# USB0_VBP2APB_WRAP_CONTROLLER_VBP_CORE_ADDR_MAP register map
Vendor: Texas Instruments
Registers are 32-bit, access per field, reset 0x0 unless marked. A register's access mark holds for its fields unless they carry their own. Offsets are as the file gives them; [hi:lo] are bit positions; {n}, {i} and the like mark numbered series; 'fields as' and 'values as' point back to an identical list.

## USB0_VBP2APB_WRAP_CONTROLLER_VBP_CORE_ADDR_MAP (part 4 of 9)
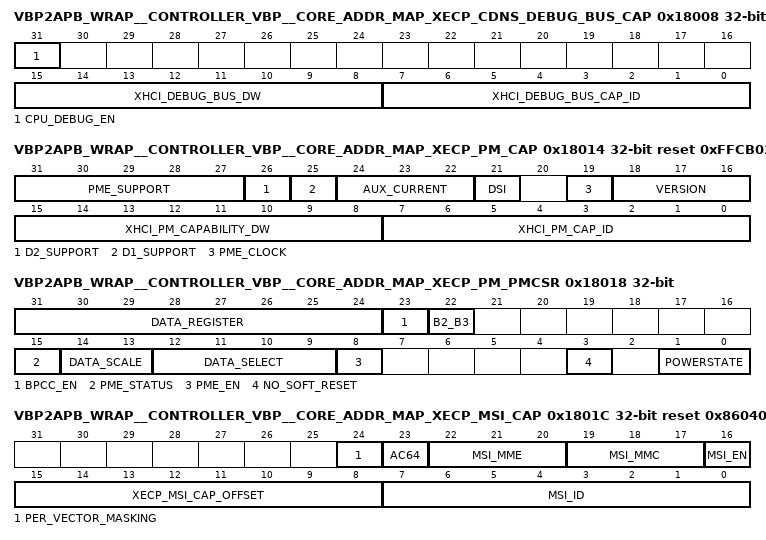
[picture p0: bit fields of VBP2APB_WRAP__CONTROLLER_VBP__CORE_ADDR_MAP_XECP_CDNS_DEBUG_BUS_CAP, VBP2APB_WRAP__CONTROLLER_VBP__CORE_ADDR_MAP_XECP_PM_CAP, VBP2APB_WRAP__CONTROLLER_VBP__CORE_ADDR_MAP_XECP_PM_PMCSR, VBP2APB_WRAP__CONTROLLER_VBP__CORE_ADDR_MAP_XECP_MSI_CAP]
0x18008 VBP2APB_WRAP__CONTROLLER_VBP__CORE_ADDR_MAP_XECP_CDNS_DEBUG_BUS_CAP reset 0x3C4 — xHCI Debug Bus Capability. This is a vendor defined capability. Please refer to Integration Guide for further details of debug bus usage.
  [31] CPU_DEBUG_EN rw — Debug Bus Enable, RW. When 0, allows the xhci_debug_sel primary input to control selection of Debug Bus sources. When 1, allows the cpu_debug_bus_sel field in the XECP_CDNS_DEBUG_BUS_CTRL register to control selection of Debug Bus sources. Default value after reset is '0'.
  [15:8] XHCI_DEBUG_BUS_DW ro — Next Capability Pointer, RO. This field indicates the location of the next capability with respect to the effective address of this capability.
  [7:0] XHCI_DEBUG_BUS_CAP_ID ro — Capability ID, RO. This field identifies the extended capability. For xHCI Debug Bus its' value is 196.
0x1800C VBP2APB_WRAP__CONTROLLER_VBP__CORE_ADDR_MAP_XECP_CDNS_DEBUG_BUS_CTRL — xHCI Debug Bus Control. This is a vendor defined capability. Please refer to Integration Guide for further details of debug bus usage.
  [4:0] CPU_DEBUG_BUS_SEL rw — Debug Bus Select, RW. Value of this field determines a source of Debug Bus. Default value after reset is 0.
0x18010 VBP2APB_WRAP__CONTROLLER_VBP__CORE_ADDR_MAP_XECP_CDNS_DEBUG_BUS_STATUS ro — xHCI Debug Bus Status. This is a vendor defined capability. Please refer to Integration Guide for further details of debug bus usage.
  [31:0] XHCI_DEBUG_BUS — Debug Bus, RO. Debug Bus current value. Note for multi-bit probes, this register is only suitable for analysing a static value due to simplified clock domain synchronisation
0x18014 VBP2APB_WRAP__CONTROLLER_VBP__CORE_ADDR_MAP_XECP_PM_CAP reset 0xFFCB0203 — Extended Power Management capability register. Defined in section 7.3 of xHCI specification. Reuses power management structures defined in PCI bus Power Management specification. This register may be read from or written to at any time, including whilst the CNR field in the USBSTS register is high.
  [31:27] PME_SUPPORT ro — Power Management Capabilities: PME_Support. Default = device specific. This 5-bit field indicates the power states in which the function may assert PME#. A value of '0' for any bit indicates that the function is not capable of asserting the PME# signal while in that power state. Encodings: Bit 0 set: X XXX1b - PME# can be asserted from D0, Bit 1 set: X XX1Xb - PME# can be asserted from D1, Bit 2 set: X X1XXb - PME# can be asserted from D2, Bit 3 set: X 1XXXb - PME# can be asserted from D3hot, Bit 4 set: 1 XXXXb - PME# can be asserted from D3cold
  [26] D2_SUPPORT ro — Power Management Capabilities: D2_Support. Default = device specific. If this bit is a '1', this function supports the D2 Power Management State. Functions that do not support D2 must always return a value of '0' for this bit.
  [25] D1_SUPPORT ro — Power Management Capabilities: D1_Support. Default = device specific. If this bit is a '1', this function supports the D1 Power Management State. Functions that do not support D1 must always return a value of '0' for this bit.
  [24:22] AUX_CURRENT rw — Power Management Capabilities: Aux_Current. Default = device specific. This 3 bit field reports the 3.3Vaux auxiliary current requirements for the PCI function. If the Data Register field of XECP_PM_PMCSR has been implemented by this function: - reads of this field must return a value of '000', - the Data Register takes precedence over this field for 3.3Vaux current requirement reporting. If PME# generation from D3cold is not supported by the Function [XECP_PM_CAP[15]='0'], this field must return a value of '000' when read. For functions that support PME# from D3cold, and do not implement the Data Register, the following bit encoding for maximum current required apply : '111': 375 mA, '110': 320 mA, '101': 270 mA, '100': 220 mA, '011': 160 mA, '010': 100 mA, '001': 55 mA, '000': 0 [self powered].
  [21] DSI ro — Power Management Capabilities: DSI. Default = device specific. The Device Specific Initialization bit indicates whether special initialization of this function is required [beyond the standard PCI configuration header] before the generic class device driver is able to use it. Note that this bit is not used by some operating systems. Microsoft Windows and Windows NT, for instance, do not use this bit to determine whether to use D3. Instead, they use the drivers capabilities to determine this. A '1' indicates that the function requires a device specific initialization sequence following transition to the D0 uninitialized state. For more information refer to Section 8.3. of PCI bus Power Management specification.
  [19] PME_CLOCK ro — Power Management Capabilities: PME Clock. Default = '0'. When this bit is a '1', it indicates that the function relies on the presence of the PCI clock for PME# operation. When this bit is a '0', it indicates that no PCI clock is required for the function to generate PME#. Functions that do not support PME# generation in any state must return '0' for this field.
  [18:16] VERSION ro — Power Management Capabilities: Version. Default = '011'. A value of '011' indicates that this function complies with revision 1.2 of the PCI Power Management Interface Specification.
  [15:8] XHCI_PM_CAPABILITY_DW ro — XHCI_PM_CAPABILITY_DW. Next Item Pointer. This field provides an offset pointing to the location of next item in the functions capability list.
  [7:0] XHCI_PM_CAP_ID ro — XHCI_PM_CAP_ID. Power Management capability ID.
0x18018 VBP2APB_WRAP__CONTROLLER_VBP__CORE_ADDR_MAP_XECP_PM_PMCSR access not given — Extended Power Management Control/Status register. Defined in section 7.3 of xHCI specification. Reuses power management structures defined in PCI bus Power Management specification. This register may be read from or written to at any time, including whilst the CNR field in the USBSTS register is high.
  [31:24] DATA_REGISTER ro — Data register. This register is used to report the state dependent data requested by the Data_Select field of XECP_PM_PMCSR register. The value of Data register is scaled by the value reported by the Data_Scale field of XECP_PM_PMCSR register.
  [23] BPCC_EN ro — PMCSR Bridge Support Extensions: BPCC_En [Bus Power/Clock Control Enable]. External strap or internally hardwired. A '1' indicates that the bus power/clock control mechanism as defined in Section 4.7.1 PCI bus Power Management specification is enabled. A '0' indicates that the bus power/clock control policies defined in Section 4.7.1 PCI bus Power Management specification have been disabled. When the Bus Power/Clock Control mechanism is disabled, the bridges Power Management Control/Status Register PowerState field cannot be used by the system software to control the power or clock of the bridges secondary bus.
  [22] B2_B3 ro — PMCSR Bridge Support Extensions: B2_B3# [B2/B3 support for D3hot]. External strap or internally hardwired. The state of this bit determines the action that is to occur as a direct result of programming the function to D3hot. A '1' indicates that when the bridge function is programmed to D3hot, its secondary buss PCI clock will be stopped [B2]. A '0' indicates that when the bridge function is programmed to D3hot, its secondary bus will have its power removed [B3]. This bit is only meaningful if bit BPCC_En of XECP_PM_PMCSR register is a '1'. Refer to Section 4.7.1 of PCI bus Power Management specification for details.
  [15] PME_STATUS — Power Management Control/Status Register: PME_Status. This bit is set when the function would normally assert the PME# signal independent of the state of the PME_En bit. Writing a '1' to this bit will clear it and cause the function to stop asserting a PME# [if enabled]. Writing a '0' has no effect. This bit defaults to '0' if the function does not support PME# generation from D3cold. If the function supports PME# from D3cold, then this bit is sticky and must be explicitly cleared by the operating system each time the operating system is initially loaded. (access R/W1TC)
  [14:13] DATA_SCALE ro — Power Management Control/Status Register: Data_Scale. Default = device specific. This 2-bit read-only field indicates the scaling factor to be used when interpreting the value of the Data register field of XECP_PM_PMCSR register. The value and meaning of this field will vary depending on which data value has been selected by the Data_Select field of this register. This field is a required component of the Data register and must be implemented if the Data register is implemented. If the Data register has not been implemented, this field must return zero when read. Refer to Section 3.2.6 of PCI bus Power Management specification for more details.
  [12:9] DATA_SELECT rw — Power Management Control/Status Register: Data_Select. Default = zero. This 4-bit field is used to select, which data is to be reported through the Data register and Data_Scale fields of XECP_PM_PMCSR register. This field is a required component of the Data register and must be implemented if the Data register is implemented. If the Data register field of XECP_PM_PMCSR is not implemented, this field should be read only and return zero when read. Refer to Section 3.2.6 of PCI bus Power Management for more details.
  [8] PME_EN rw — Power Management Control/Status Register: PME_En. A '1' in this field enables the function to assert PME#. When '0', PME# assertion is disabled. This bit defaults to '0' if the function does not support PME# generation from D3cold. If the function supports PME# from D3cold, then this bit is sticky and must be explicitly cleared by the operating system each time it is initially loaded. Functions that do not support PME# generation from any D-state [i.e., XECP_PM_CAP[15:11] = '00000'], may hardwire this bit to be read-only always returning a '0' when read by system software.
  [3] NO_SOFT_RESET ro — Power Management Control/Status Register: No_Soft_Reset. Default = device specific. When set to '1', this bit indicates that devices transitioning from D3hot to D0 because of PowerState commands do not perform an internal reset. Configuration Context is preserved. Upon transition from the D3hot to the D0 Initialized state, no additional operating system intervention is required to preserve Configuration Context beyond writing the PowerState bits. When cleared to '0', devices do perform an internal reset upon transitioning from D3hot to D0 via software control of the PowerState bits. Configuration Context is lost when performing the soft reset. Upon transition from the D3hot to the D0 state, full reinitialization sequence is needed to return the device to D0 Initialized. Regardless of this bit, devices that transition from D3hot to D0 by a system or bus segment reset will return to the device state D0 Uninitialized with only PME context preserved if PME is supported and enabled.
  [1:0] POWERSTATE rw — Power Management Control/Status Register: PowerState. Default = zero. This 2-bit field is used both to determine the current power state of a function and to set the function into a new power state. Possible values: '00': D0, '01': D1, '10': D2, '11': D3hot. If software attempts to write an unsupported, optional state to this field, the write operation must complete normally on the bus. however, the data is discarded and no state change occurs.
0x1801C VBP2APB_WRAP__CONTROLLER_VBP__CORE_ADDR_MAP_XECP_MSI_CAP reset 0x860405 — Message Signaled Interrupts (MSI) configuration register. This register may be read at any time, including whilst the CNR field in the USBSTS register is high. It can be written only when controller is stopped (bit HCH of USBSTS register is '0').
  [24] PER_VECTOR_MASKING ro — MSI Message Control: Per-vector masking capable. If '1', the function supports MSI per-vector masking. If '0', the function does not support MSI per-vector masking. This bit is read only. Not Supported in this configuration
  [23] AC64 ro — MSI Message Control: 64 bit address capable. If '1', the function is capable of generating sending a 64-bit message address. If '0', the function is not capable of generating sending a 64-bit message address. This bit is read only.
  [22:20] MSI_MME rw — MSI Message Control: Multiple Message Enable. Software writes to this field to indicate the number of allocated vectors [equal to or less than the number of requested vectors]. The number of allocated vectors is aligned to a power of two. If a function requests four vectors [indicated by a Multiple Message Capable encoding of 010], system software can allocate either four, two, or one vector by writing a '010', '001', or '000' to this field, respectively. When MSI is enabled, a function will be allocated at least one vector. The encoding is defined as: '000': 1, '001': 2, '010': 4, '011': 8, '100': 16, '101': 32, '110': Reserved, '111': Reserved. This fields state after reset is '000'.
  [19:17] MSI_MMC ro — MSI Message Control: Multiple Message Capable. System software reads this field to determine the number of requested vectors. The number of requested vectors must be aligned to a power of two [if a function requires three vectors, it requests four by initializing this field to '010']. The encoding is defined as: '000': 1, '001': 2, '010': 4, '011': 8, '100': 16, '101': 32, '110': Reserved, '111': Reserved. This field is read only.
  [16] MSI_EN rw — MSI Message Control: MSI enable. System configuration software sets this bit to enable MSI. A device driver is prohibited from writing this bit to mask a functions service request. If '0', the function is prohibited from using MSI to request service. This bits state after reset is '0' [MSI is disabled].
  [15:8] XECP_MSI_CAP_OFFSET ro — Pointer to the next item in the capabilities list. A non-zero value in this field indicates a relative offset, in 32-bit words, from this 32-bit word to the beginning of the next extended capability.
  [7:0] MSI_ID ro — Capability ID for Message Signaled Interrupts. The value of 05h in this field identifies the function as being MSI capable.
0x18020 VBP2APB_WRAP__CONTROLLER_VBP__CORE_ADDR_MAP_XECP_MSI_ADDR_L access not given — Message Lower Address for MSI. If the Message Enable bit of MSI Message Control (bit 16 of the XCEP_MSI_CAP register) is set, the contents of this register specify the DWORD-aligned address (bits [31:02]) for the MSI memory write transaction. bits [1:0] are driven to zero during the address phase. This register may be read from at any time, including whilst the CNR field in the USBSTS register is high. It can be written only when controller is stopped (bit HCH of USBSTS register is '0').
  [31:2] MSI_ADDR_LOW rw — Message Lower Address for MSI. System-specified message address. If the Message Enable bit of MSI Message Control [bit 16 of the XCEP_MSI_CAP register] is set, the contents of this register specify the DWORD-aligned address for the MSI memory write transaction. Note: This field should not be written unless the Message Enable bit of MSI Message Control [bit 16 of the XCEP_MSI_CAP register] is cleared. This field is read/write.
0x18024 VBP2APB_WRAP__CONTROLLER_VBP__CORE_ADDR_MAP_XECP_MSI_ADDR_H rw — Message Upper Address for MSI. System-specified message upper address. This register is optional and is implemented only if the function supports a 64-bit message address (AC64 bit of MSI Message Control, see XCEP_MSI_CAP register). If the Message Enable bit of MSI Message Control (bit 16 of the XCEP_MSI_CAP register), the contents of this register (if nonzero) specify the upper 32-bits of a 64-bit message address (bits [63:32]). If the contents of this register are zero, the function uses the 32 bit address specified by the message address register. It can be written only when controller is stopped (bit HCH of USBSTS register is '0').
  [31:0] MSI_ADDR_HI — Message Upper Address for MSI. System-specified message upper address. Note: This field should not be written unless the Message Enable bit of MSI Message Control [bit 16 of the XCEP_MSI_CAP register] is cleared. This field is read/write.
0x18028 VBP2APB_WRAP__CONTROLLER_VBP__CORE_ADDR_MAP_XECP_MSI_DATA — Message data for MSI. This register may be read from to at any time, including whilst the CNR field in the USBSTS register is high. It can be written only when controller is stopped (bit HCH of USBSTS register is '0').
  [15:0] MSI_DATA rw — System-specified message data. If the Message Enable bit of MSI Message Control [bit 16 of the XCEP_MSI_CAP register] is set, the message data is driven onto the lower word [bits [15:0]] of the memory write transactions data phase. Bits [31:16] are driven to zero during the memory write transactions data phase. C/BE[3::0]# are asserted during the data phase of the memory write transaction. The Multiple Message Enable field of MSI Message Control [see MSI_MME field of XCEP_MSI_CAP register] defines the number of low order message data bits the function is permitted to modify to generate its system software allocated vectors. For example, a Multiple Message Enable encoding of '010' indicates the function has been allocated four vectors and is permitted to modify message data bits 1 and 0 [a function modifies the lower message data bits to generate the allocated number of vectors]. If the Multiple Message Enable field is '000', the function is not permitted to modify the message data. Note: This field should not be written unless the Message Enable bit of MSI Message Control [bit 16 of the XCEP_MSI_CAP register] is cleared. This field is read/write.
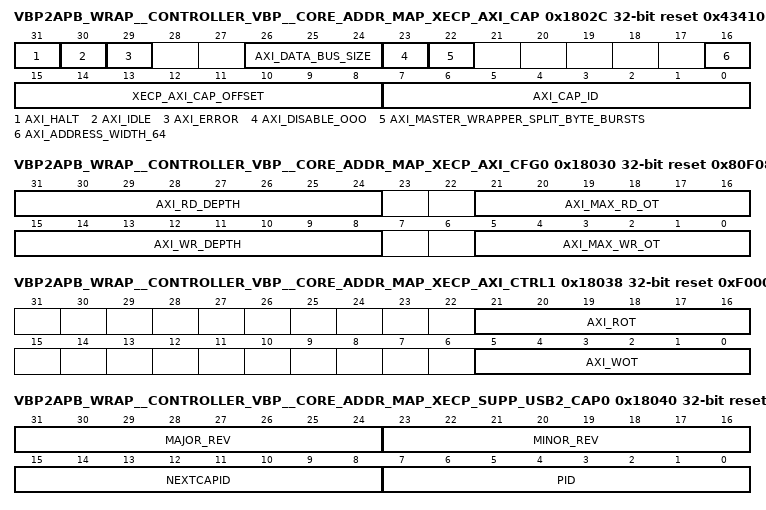
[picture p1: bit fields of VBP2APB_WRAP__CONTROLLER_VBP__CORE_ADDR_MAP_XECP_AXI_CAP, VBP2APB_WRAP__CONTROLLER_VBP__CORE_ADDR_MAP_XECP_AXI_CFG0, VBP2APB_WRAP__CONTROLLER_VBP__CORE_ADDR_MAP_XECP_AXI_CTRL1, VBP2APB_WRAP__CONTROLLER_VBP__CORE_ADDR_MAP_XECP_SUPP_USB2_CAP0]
0x1802C VBP2APB_WRAP__CONTROLLER_VBP__CORE_ADDR_MAP_XECP_AXI_CAP access not given reset 0x434105C2 — AXI Master Wrapper Extended Capability. This register may be read from or written to at any time, including whilst the CNR field in the USBSTS register is high. This is a vendor defined capability.
  [31] AXI_HALT rw — AXI HALT, RW. The AXI Master wrapper's control bit. When set, the AXI Master wrapper will complete current CORE REQ [or IRQ] and stop acknowledging next ones. If the xHC is stopped the AXI Master wrapper is halted automatically. If the xHC is started the AXI Master wrapper is resumed automatically. Software should set this bit to stop the AXI Master issuing new AXI transactions. It may then use the IDLE bit to determine when all previous transactions were completed. Note: The AXI Master wrapper will execute halted only if xHC stopped its internal operation.
  [30] AXI_IDLE ro — AXI IDLE, RO. Information about the AXI Master wrapper state: '0': no pending action required by the AXI Master wrapper, '1': the AXI Master wrapper has outstanding transactions. Note: HCH halted bit will not be asserted if the AXI Master wrapper is not idle.
  [29] AXI_ERROR — AXI ERROR, RW1C. Provides an information about AXI ERROR response on B or R channel. This flag is cleared by writing '1' to it. Once set it is held until cleared. The condition setting this register will also assert HSE. This flag may be read by software while handling HSE assertion to determine if the case was AXI ERROR reponse. (access R/W1TC)
  [26:24] AXI_DATA_BUS_SIZE ro — AXI_DATA_WORD_SIZE, RO. AXI data buses size capability. It uses AXI AxSIZE Encoding. Values of 64-bit ['011'] or 128-bit ['100'] are supported through compile time configuration.
  [23] AXI_DISABLE_OOO ro — Disable Out-Of-Order R channel responses [AXI_MASTER_WRAPPER_DISABLE_OOO], RO. This relates to number of IDs used at AXI IF. If Out-Of-Order R channel responses are not disabled this count may be greater than one and in such a case the R channel responses may come Out-Of-Order. The flag gives information about number of used AXI IDs: '0': single ID, '1': multiple IDs.
  [22] AXI_MASTER_WRAPPER_SPLIT_BYTE_BURSTS ro — AXI_MASTER_WRAPPER_SPLIT_BYTE_BURSTS, RO. Presents information about AXI byte burst capability: '0': no byte bursts, '1': byte bursts enabled.
  [16] AXI_ADDRESS_WIDTH_64 ro — AXI address bus width capability, RO. '0': 32-bit address bus width, '1': 64-bit address bus width.
  [15:8] XECP_AXI_CAP_OFFSET ro — Next capability Offset, RO. This field points to the xHC MMIO space offset of the next xHCI extended capability pointer. A value of 00h indicates the end of the extended capability list. A non-zero value in this register indicates a relative offset, in Dwords, from this Dword to the beginning of the next extended capability.
  [7:0] AXI_CAP_ID ro — VEND_DEF_AXI_MASTER_WRAPPER_CAP_ID, RO. Vendor defined xHCI Extended Capability: 0xC2. This field identifies the AXI wrapper xHCI Extended capability.
0x18030 VBP2APB_WRAP__CONTROLLER_VBP__CORE_ADDR_MAP_XECP_AXI_CFG0 ro reset 0x80F080F — AXI Master Wrapper Extended Capability Configuration Register. This register may be read from or written to at any time, including whilst the CNR field in the USBSTS register is high.
  [31:24] AXI_RD_DEPTH — AXI READ_BUFFER_DEPTH, RO. Number of AXI Read beats that can be buffered by the AXI Master wrapper. The value written to this field should be the Number of AXI Read beats that can be buffered by the AXI Master wrapper minus 1.
  [21:16] AXI_MAX_RD_OT — AXI MAX_READ_OUTSTANDING, RO. Maximum number of Outstanding Read Transactions initiated by the AXI Master wrapper in AR channel. The value written to this field should be the Maximum number of Outstanding Read Transactions initiated by the AXI Master wrapper minus 1, thus the Maximum number of Outstanding Read Transactions is 1 more than the programmed value.
  [15:8] AXI_WR_DEPTH — AXI WRITE_BUFFER_DEPTH, RO. Number of AXI Write beats that can be buffered by the AXI Master wrapper. The value written to this field should be the number of AXI Write beats that can be buffered by the AXI Master wrapper minus 1.
  [5:0] AXI_MAX_WR_OT — AXI MAX_WRITE_OUTSTANDING, RO. Maximum number of Outstanding Write Transactions initiated by the AXI Master wrapper in AW channel. The value written to this field should be the Maximum number of Outstanding Write Transactions initiated by the AXI Master wrapper minus 1, thus the Maximum number of Outstanding Write Transactions is 1 more than the programmed value.
0x18034 VBP2APB_WRAP__CONTROLLER_VBP__CORE_ADDR_MAP_XECP_AXI_CTRL0 reset 0xF — AXI Master Wrapper Extended Capability Control Register 0. This register may be read from or written to at any time, including whilst the CNR field in the USBSTS register is high.
  [3:0] AXI_BMAX rw — AXI BMAX, RW. The register controls maximum burst length - it is used by the AXI Master wrapper to determine maximum value of AxLEN. It uses AXI AxLEN encoding. Default value is the maximum supported one and it is implementation specific. Writing value greater than maximum will result in setting the register to its defaults. This register can be written only when the AXI Master wrapper is halted [AXI_HALT set to '1'] and idle [AXI_IDLE is '1']. Note: This register should only be written to during the register initialisation process
0x18038 VBP2APB_WRAP__CONTROLLER_VBP__CORE_ADDR_MAP_XECP_AXI_CTRL1 reset 0xF000F — AXI Master Wrapper Extended Capability Control Register 1. This register may be read from or written to at any time, including whilst the CNR field in the USBSTS register is high.
  [21:16] AXI_ROT rw — AXI READ_OUTSTANDING, RW. Number of outstanding read transactions that can be initiated by the AXI Master wrapper. Default value of this field is MAX_READ_OUTSTANDING-1 [see AXI_MAX_RD_OT field of XECP_AXI_CFG0 register]. Writing value greater than the default will result in setting the register to its defaults. This register can be written only when the AXI Master wrapper is halted [AXI_HALT set to '1'] and idle [AXI_IDLE is '1']. The value written to this field should be the requested number of outstanding read transactions minus 1, thus the actual number of possible outstanding read transactions is one more than the programmed value. Note: This register should only be written to during the register initialisation process
  [5:0] AXI_WOT rw — AXI WRITE_OUTSTANDING, RW. Number of outstanding write transactions that can be initiated by the AXI Master wrapper. Default value of this field is MAX_WRITE_OUTSTANDING-1 [see AXI_MAX_WR_OT field of XECP_AXI_CFG0]. Writing value greater than the default will result in setting the register to its defaults. This register can be written only when the AXI Master wrapper is halted [AXI_HALT set to '1'] and idle [AXI_IDLE is '1']. The value written to this field should be the requested number of outstanding write transactions minus 1, thus the actual number of possible outstanding write transactions is one more than the programmed value. Note: This register should only be written to during the register initialisation process
0x1803C VBP2APB_WRAP__CONTROLLER_VBP__CORE_ADDR_MAP_XECP_AXI_CTRL2 reset 0x1 — AXI Master Wrapper Extended Capability Control Register 2. This register may be read from or written to at any time, including whilst the CNR field in the USBSTS register is high.
  [7:0] AXI_WTHRES rw — AXI Write Buffer Threshold, RW. When performing an AXI write burst this field specifies the minimum number of required AXI beats buffered prior to starting the burst on AXI W-Channel by asserting wvalid. This allows a user to balance the requirement for minimal latency with the requirement for low bus utilisation during bursts. Burst lengths smaller than or equal to this threshold will be buffered completely and then output on W-Channel. Burst lengths greater than this threshold will output the burst on the W-Channel such that the first AXI_WTHRES beats will be continuously with no drop of WVALID, beats thereafter may or may not be continuous depending on availability of data. Legal values are between 1 and [AXI_WDD-1]. A value of 1 means that the burst is started on W-Channel as soon as any data is available without any additional delay. A value of 0 is reserved and should not be used as may lead to unpredictable behaviour. This register can be written only when the AXI Master wrapper is halted [AXI_HALT set to '1'] and idle [AXI_IDLE is '1']. Note: This register should only be written to during the register initialisation process.
0x18040 VBP2APB_WRAP__CONTROLLER_VBP__CORE_ADDR_MAP_XECP_SUPP_USB2_CAP0 ro reset 0x2000802 — xHCI Supported Protocol Capability.
  [31:24] MAJOR_REV — Major Specification Release Number in Binary-Coded Decimal [i.e.,version 3.x is 03h]. This field identifies the major release number component of the specification with which the xHC is compliant.
  [23:16] MINOR_REV — Minor Specification Release Number in Binary-Coded Decimal [i.e.,version x.10 is 10h]. This field identifies the minor release number component of the specification with which the xHC is compliant.
  [15:8] NEXTCAPID — This field indicates the location of the next capability with respect to the effective address of this capability. Refer to Table 142 of xHCI specification for more information on this field.
  [7:0] PID — Capability ID. The value identifies the capability as Supported Protocol.
0x18044 VBP2APB_WRAP__CONTROLLER_VBP__CORE_ADDR_MAP_XECP_SUPP_USB2_CAP1 ro reset 0x20425355 — xHCI Supported Protocol Capability.
  [31:0] USB_STRING — Name String, RO. This field is a mnemonic name string that references the specification with which the xHC is compliant. Four ASCII characters may be defined. Allowed characters are: alphanumeric, space, and underscore. Alpha characters are case sensitive. Refer to section 7.2.2 of xHCI specification for defined values.
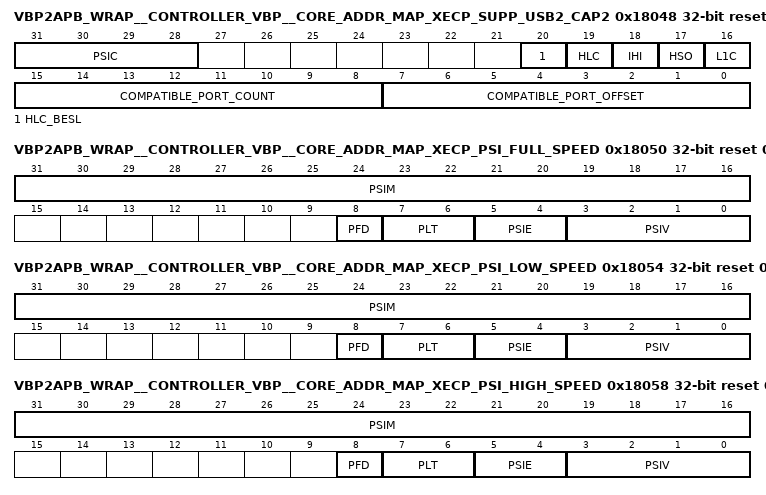
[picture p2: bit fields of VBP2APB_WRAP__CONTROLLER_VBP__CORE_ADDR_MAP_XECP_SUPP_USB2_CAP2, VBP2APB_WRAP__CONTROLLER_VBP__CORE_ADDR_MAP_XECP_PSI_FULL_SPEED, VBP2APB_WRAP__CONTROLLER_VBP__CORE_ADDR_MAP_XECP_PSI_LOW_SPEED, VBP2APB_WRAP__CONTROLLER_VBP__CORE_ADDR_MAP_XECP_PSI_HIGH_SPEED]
0x18048 VBP2APB_WRAP__CONTROLLER_VBP__CORE_ADDR_MAP_XECP_SUPP_USB2_CAP2 ro reset 0x30190101 — xHCI Supported Protocol Capability. USB 2.0 protocol
  [31:28] PSIC — Protocol Speed ID Count: 3, USB 2.0 Speed [High, Full, Low]. This field indicates the number of Protocol Speed ID [PSI] Dwords that the xHCI Supported Protocol Capability data structure contains. If this field is non-zero, then all speeds supported by the protocol shall be defined using PSI Dwords, i.e. no implied Speed ID mappings apply.
  [20] HLC_BESL — HLC_BESL. In xHCI 1.0 specification this field is reserved RsvdP, see section 7.2.2.1.3. The field is described in xHCI 1.1 specification: BESL LPM Capability [BLC], RO. Default = Implementation dependent. If this bit is set to '1', the ports described by this xHCI Supported Protocol Capability shall apply BESL timing to BESL and BESLD fields of the PORTPMSC and PORTHLPMC registers, as defined in Table 13. If this bit is cleared to '0', the ports described by this xHCI Supported Protocol Capability shall apply HIRD timing to BESL and BESLD fields of the PORTPMSC and PORTHLPMC registers, as defined in Table 13. Refer to section 4.23.5.1.1.1 for more information. Note the BESL LMP Capability support [i.e. HLE = 1 and BLC = 1] shall be mandatory for all xHCI 1.1 compliant xHCs.
  [19] HLC — Hardware LPM Capability. Default = Implementation dependent. If this bit is set to '1', the ports described by this xHCI Supported Protocol Capability support hardware controlled USB2 Link Power Management. Refer to section 4.23.5.1.1.1 of xHCI specification.
  [18] IHI — Integrated Hub Implemented. Default = Implementation dependent. If this bit is cleared to '0', the Root Hub to External xHC port mapping adheres to the default mapping described in section 4.24.2.1 of xHCI specification. If this bit is set to '1', the Root Hub to External xHC port mapping does not adhere to the default mapping described in section 4.24.2.1 of xHCI specification, and an ACPI or other mechanism is required to define the mapping.
  [17] HSO — High-speed Only. Default = Implementation dependent. If this bit is cleared to '0', the USB2 ports described by this capability are Low-, Full-, and High-speed capable. If this bit is set to '1', the USB2 ports described by this capability are High-speed only, e.g. the ports do not support Low- or Full-speed operation. High-speed only implementations may introduce a Tier mismatch, refer to section 4.24.2 of xHCI specification for more information.
  [16] L1C — If '1'LPM is supported [mandatory in xHCI1_00]. In xHCI specification this field is reserved RsvdP, see section 7.2.2.1.3
  [15:8] COMPATIBLE_PORT_COUNT — This field identifies the number of consecutive Root Hub Ports [starting at the Compatible Port Offset] that support this protocol. Valid values are 1 to MaxPorts.
  [7:0] COMPATIBLE_PORT_OFFSET — This field specifies the starting Port Number of Root Hub Ports that support this protocol. Valid values are 1 to MaxPorts.
0x1804C VBP2APB_WRAP__CONTROLLER_VBP__CORE_ADDR_MAP_XECP_SUPP_USB2_PROTOCOL_SLOT_TYPE ro — Protocol Slot Type. xHCI Supported Protocol Capability
  [4:0] PST — This field specifies the Protocol Slot Type value, which may be specified when allocating Device Slots that support this protocol. Valid values are 0 to 31. Refer to sections 4.6.3 and 7.2.2.1.4 of xHCI specification. The value of the Protocol Slot Type field declared by a xHCI Supported Protocol Capability structure is unique to an xHC implementation. Software shall not assume a fixed mapping of the Protocol Slot Type value to a specific type of Supported Protocol. Note that for compatibility reasons, the Protocol Slot Type value of 0 is the exception to this rule and reserved for the USB Protocol Device Slot type.
0x18050 VBP2APB_WRAP__CONTROLLER_VBP__CORE_ADDR_MAP_XECP_PSI_FULL_SPEED ro reset 0xC0021 — Protocol Speed ID, xHCI Supported Protocol Capability
  [31:16] PSIM — Protocol Speed ID Mantissa. This field defines the mantissa that shall be applied to the PSIE when calculating the maximum bit rate represented by this PSI Dword.
  [8] PFD — PSI Full-duplex. If this bit is '1' the link is full-duplex, and if '0' the link is half-duplex.
  [7:6] PLT — PSI Type. This field identifies whether the PSI Dword defines a symmetric or asymmetric bit rate, and if asymmetric, then this field also indicates if this Dword defines the receive or transmit bit rate. Note that the Asymmetric PSI Dwords shall be paired, i.e. an Rx immediately followed by a Tx, and both Dwords shall define the same value for the PSIV. PLT Values and corresponding bit rate: 0: Symmetric [Single PSI Dword] 1: Reserved 2: Asymmetric Rx [Paired with Asymmetric Tx PSI Dword] 3: Asymmetric Tx [Immediately follows Rx Asymmetric PSI Dword].
  [5:4] PSIE — Protocol Speed ID Exponent. This field defines the base 10 exponent times 3, that shall be applied to the Protocol Speed ID Mantissa when calculating the maximum bit rate represented by this PSI Dword. PSIE Values and corresponding bit rates: 0: Bits per second 1: Kb/s 2: Mb/s 3: Gb/s .
  [3:0] PSIV — Protocol Speed ID Value. If a device is attached that operates at the bit rate defined by this PSI Dword, then the value of this field shall be reported in the Port Speed field of PORTSC register [5.4.8 of xHCI specification] of a compatible port. Note, the PSIV value of 0 is reserved and shall not be defined by a PSI.
0x18054 VBP2APB_WRAP__CONTROLLER_VBP__CORE_ADDR_MAP_XECP_PSI_LOW_SPEED ro reset 0x5DC0012 — Protocol Speed ID, xHCI Supported Protocol Capability
  [31:16] PSIM — Protocol Speed ID Mantissa. This field defines the mantissa that shall be applied to the PSIE when calculating the maximum bit rate represented by this PSI Dword.
  [8] PFD — PSI Full-duplex. If this bit is '1' the link is full-duplex, and if '0' the link is half-duplex.
  [7:6] PLT — PSI Type. This field identifies whether the PSI Dword defines a symmetric or asymmetric bit rate, and if asymmetric, then this field also indicates if this Dword defines the receive or transmit bit rate. Note that the Asymmetric PSI Dwords shall be paired, i.e. an Rx immediately followed by a Tx, and both Dwords shall define the same value for the PSIV. PLT Values and corresponding bit rate: 0: Symmetric Single [PSI Dword] 1: Reserved 2: Asymmetric Rx [Paired with Asymmetric Tx PSI Dword] 3: Asymmetric Tx [Immediately follows Rx Asymmetric PSI Dword].
  [5:4] PSIE — Protocol Speed ID Exponent. This field defines the base 10 exponent times 3, that shall be applied to the Protocol Speed ID Mantissa when calculating the maximum bit rate represented by this PSI Dword. PSIE Values and corresponding bit rates: 0: Bits per second 1: Kb/s 2: Mb/s 3: Gb/s .
  [3:0] PSIV — Protocol Speed ID Value. If a device is attached that operates at the bit rate defined by this PSI Dword, then the value of this field shall be reported in the Port Speed field of PORTSC register [5.4.8 of xHCI specification] of a compatible port. Note, the PSIV value of 0 is reserved and shall not be defined by a PSI.
0x18058 VBP2APB_WRAP__CONTROLLER_VBP__CORE_ADDR_MAP_XECP_PSI_HIGH_SPEED ro reset 0x1E00023 — Protocol Speed ID, xHCI Supported Protocol Capability
  fields as VBP2APB_WRAP__CONTROLLER_VBP__CORE_ADDR_MAP_XECP_PSI_LOW_SPEED
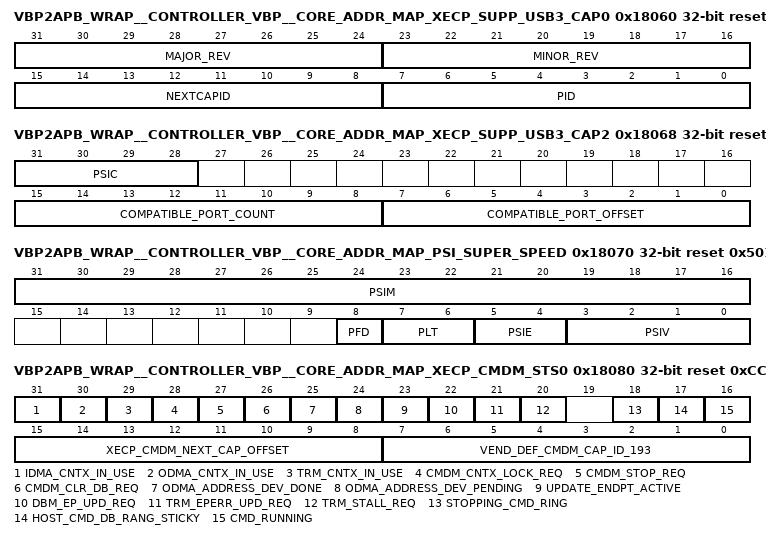
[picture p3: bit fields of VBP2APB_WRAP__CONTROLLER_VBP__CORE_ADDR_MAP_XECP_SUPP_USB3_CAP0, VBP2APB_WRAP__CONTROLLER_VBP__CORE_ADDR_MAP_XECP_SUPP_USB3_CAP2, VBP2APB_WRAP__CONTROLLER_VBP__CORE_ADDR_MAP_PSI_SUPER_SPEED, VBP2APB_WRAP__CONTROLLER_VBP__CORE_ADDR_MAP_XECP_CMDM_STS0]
0x18060 VBP2APB_WRAP__CONTROLLER_VBP__CORE_ADDR_MAP_XECP_SUPP_USB3_CAP0 ro reset 0x3000802 — xHCI Supported Protocol Capability.
  fields as VBP2APB_WRAP__CONTROLLER_VBP__CORE_ADDR_MAP_XECP_SUPP_USB2_CAP0
0x18064 VBP2APB_WRAP__CONTROLLER_VBP__CORE_ADDR_MAP_XECP_SUPP_USB3_CAP1 ro reset 0x20425355 — xHCI Supported Protocol Capability.
  fields as VBP2APB_WRAP__CONTROLLER_VBP__CORE_ADDR_MAP_XECP_SUPP_USB2_CAP1
0x18068 VBP2APB_WRAP__CONTROLLER_VBP__CORE_ADDR_MAP_XECP_SUPP_USB3_CAP2 ro reset 0x10000102 — xHCI Supported Protocol Capability. USB 3.0 protocol
  [31:28] PSIC — Protocol Speed ID CountCount : 1, USB 3.0 Speed [Super Speed]. This field indicates the number of Protocol Speed ID [PSI] Dwords that the xHCI Supported Protocol Capability data structure contains. If this field is non-zero, then all speeds supported by the protocol shall be defined using PSI Dwords, i.e. no implied Speed ID mappings apply.
  [15:8] COMPATIBLE_PORT_COUNT — This field identifies the number of consecutive Root Hub Ports [starting at the Compatible Port Offset] that support this protocol. Valid values are 1 to MaxPorts.
  [7:0] COMPATIBLE_PORT_OFFSET — This field specifies the starting Port Number of Root Hub Ports that support this protocol. Valid values are 1 to MaxPorts.
0x1806C VBP2APB_WRAP__CONTROLLER_VBP__CORE_ADDR_MAP_XECP_SUPP_USB3_PROTOCOL_SLOT_TYPE ro — Protocol Slot Type. xHCI Supported Protocol Capability
  fields as VBP2APB_WRAP__CONTROLLER_VBP__CORE_ADDR_MAP_XECP_SUPP_USB2_PROTOCOL_SLOT_TYPE
0x18070 VBP2APB_WRAP__CONTROLLER_VBP__CORE_ADDR_MAP_PSI_SUPER_SPEED ro reset 0x50134 — Protocol Speed ID, xHCI Supported Protocol Capability
  fields as VBP2APB_WRAP__CONTROLLER_VBP__CORE_ADDR_MAP_XECP_PSI_LOW_SPEED
0x18080 VBP2APB_WRAP__CONTROLLER_VBP__CORE_ADDR_MAP_XECP_CMDM_STS0 ro reset 0xCC1 — Command Ring related status register. Command manager status debug register. This is a vendor defined capability. This register is reserved. This register should not be modified by software. It is described only for informative purposes.
  [31] IDMA_CNTX_IN_USE — Indicates that IDMA module currently owns the context access :
  [30] ODMA_CNTX_IN_USE — Indicates that ODMA module currently owns currently the context access
  [29] TRM_CNTX_IN_USE — Indicates that TRM modules owns the context access currently
  [28] CMDM_CNTX_LOCK_REQ — Indicates that Command Manager has requested a context lock.
  [27] CMDM_STOP_REQ — Indicates that Command Ring stop command is in progress.
  [26] CMDM_CLR_DB_REQ — Indicates that clearing an EP out of schedule is in progress.
  [25] ODMA_ADDRESS_DEV_DONE — Indicates that current address device command is done by ODMA.
  [24] ODMA_ADDRESS_DEV_PENDING — Indicates that ODMA has an address device command in progress.
  [23] UPDATE_ENDPT_ACTIVE — Indicates that updating of EP state is in progress
  [22] DBM_EP_UPD_REQ — Indicates that Doorbell Manager is issuing and EP update due to a doorbell ring on an EP that is in stop state
  [21] TRM_EPERR_UPD_REQ — Indicates that Transfer Ring Manager is issuing and EP update due to an EP error condition detected
  [20] TRM_STALL_REQ — Indicates that transfer ring manager is issuing and EP state update due to stall received
  [18] STOPPING_CMD_RING — Indicates that a STOP on the Command Ring is in progress
  [17] HOST_CMD_DB_RANG_STICKY — Indicates that command ring has a doorbell pending
  [16] CMD_RUNNING — Indicates that the command ring is running
  [15:8] XECP_CMDM_NEXT_CAP_OFFSET — Next capability offset
  [7:0] VEND_DEF_CMDM_CAP_ID_193 — Vendor defined capability ID. Command Ring Manager capability ID.
{0x18080+4i} VBP2APB_WRAP__CONTROLLER_VBP__CORE_ADDR_MAP_XECP_CMDM_RESERVED_{i} ro (i=1..5) — Event ring manager module reserved space. This is a vendor defined capability. This register is reserved. This register should not be accessed by software. It is described only for informative purposes.
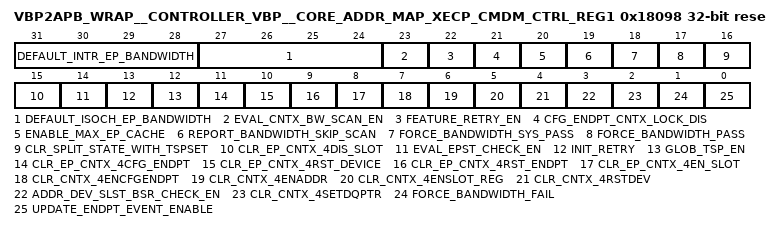
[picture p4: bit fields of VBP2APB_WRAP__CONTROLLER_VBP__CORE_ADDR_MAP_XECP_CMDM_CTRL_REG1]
0x18098 VBP2APB_WRAP__CONTROLLER_VBP__CORE_ADDR_MAP_XECP_CMDM_CTRL_REG1 rw reset 0x3580AFFC — Command Manager Control register 1. This register contains fields which control the behavior of the Command Manager in the xHCI. The functions controlled by this register are made available largely for debug/diagnostic purposes. This functionality is above and beyond that defined in the xHCI specification. This is a vendor defined capability. This register is reserved. This register should not be accessed by software. It is described only for informative purposes.
  [31:28] DEFAULT_INTR_EP_BANDWIDTH — Bandwidth calculation parameter: Default bandwidth for an Interrupt Endpoint.
  [27:24] DEFAULT_ISOCH_EP_BANDWIDTH — Bandwidth calculation parameter: Default bandwidth for an Isochronous Endpoint.
  [23] EVAL_CNTX_BW_SCAN_EN — Enable the Host Controller's Bandwidth checks for the Evaluate Context Command. Rescan the BW during evaluate context
  [22] FEATURE_RETRY_EN — Enable the EOB and NPKT==0 [called NYET condition for USB3] to be used to update a retry bit during stream switching operation. This is an internal safety feature. It should be treated as reserved bit.
  [21] CFG_ENDPT_CNTX_LOCK_DIS — Context lock mechanism to ensure command manager has exclusive access to internal context. This is a disable bit to allow software to turn off the context lock for configure endpoint command. This is a test/debug feature. '1': indicates disabled. '0': Indicates enabled
  [20] ENABLE_MAX_EP_CACHE
  [19] REPORT_BANDWIDTH_SKIP_SCAN
  [18] FORCE_BANDWIDTH_SYS_PASS
  [17] FORCE_BANDWIDTH_PASS
  [16] CLR_SPLIT_STATE_WITH_TSPSET — This bit allows engine to reset the split states when reset endpoint with TSP is posted. The split state is an internal context field in DMA engine. '0': Indicates that reset endpoint with TSP will preserve the split state. '1': Indicates that the reset endpoint with TSP will not preserve the split state.
  [15] CLR_EP_CNTX_4DIS_SLOT — '0': Disable clearing internal TRM and DMA context as well as the internal EP status signals during a disable slot command. '1': Enable clearing internal TRM and DMA context as well as the internal EP status signals during a disable slot command.
  [14] EVAL_EPST_CHECK_EN — '0': Disable evaluating the endpoint state during an Evaluate Context command, '1': Enable EP state check during an Evaluate Context command. If failed, context error will be returned.
  [13] INIT_RETRY — init_retry. Reserved to always read value of '1'.
  [12] GLOB_TSP_EN — '0': Disable the global context preservation. '1': Enable the internal context preservation for all commands that needs to preserve some of the internal context fields as a command with TSP would.
  [11] CLR_EP_CNTX_4CFG_ENDPT — '0': Disable clearing other internal EP status signals during a configure endpoint command. '1': Enable clearing other internal EP related status signals such as EP scheduled array, credit stored per EP, etc. during a configure endpoint command.
  [10] CLR_EP_CNTX_4RST_DEVICE — '0': Disable clearing other internal EP status signals during a reset device command. '1': Enable clearing other internal EP related status signals such as EP scheduled array, credit stored per EP, etc. during a reset device command.
  [9] CLR_EP_CNTX_4RST_ENDPT — '0': Disable clearing other internal EP status signals during a reset endpoint command. '1': Enable clearing other internal EP related status signals such as EP scheduled array, credit stored per EP. etc. during a reset endpoint command.
  [8] CLR_EP_CNTX_4EN_SLOT — '0': Disable clearing other internal EP status signals during an enable slot command. '1': Enable clearing other internal EP related status signals such as EP scheduled array, credit stored per EP. etc., during an enable slot command.
  [7] CLR_CNTX_4ENCFGENDPT — '0': Disable clearing internal TRM and DMA context during a configure endpoint command. '1': Enable clearing internal TRM and DMA context during a configure endpoint command.
  [6] CLR_CNTX_4ENADDR — '0': Disable clearing internal TRM and DMA context during an address device command. '1': Enable clearing internal TRM and DMA context during an address device command.
  [5] CLR_CNTX_4ENSLOT_REG — '0': Disable clearing internal TRM and DMA context during an enable slot command. '1': Enable clearing internal TRM and DMA context during an enable slot command.
  [4] CLR_CNTX_4RSTDEV — '0': Disable clearing internal TRM and DMA context during a reset device command. '1': Enable clearing internal TRM and DMA context during a reset device command.
  [3] ADDR_DEV_SLST_BSR_CHECK_EN — '0': Address device does not return the error for this condition. '1': Enable the EP state [default state] check with address device command with BSR. If failed, an event with context state error will be generated.
  [2] CLR_CNTX_4SETDQPTR — '0': Disable clearing internal TRM and DMA context during a set TR DQ pointer command. '1': Enable clearing internal TRM and DMA context during a set TR DQ pointer command.
  [1] FORCE_BANDWIDTH_FAIL — '0': Bandwidth calculation handled normally. '1': Forces a failure in the endpoint bandwidth calculation so that engine will reject a configure EP command.
  [0] UPDATE_ENDPT_EVENT_ENABLE — '0': Disable generation of the completion event. '1': Enable the command manager to generate a completion event after an EP state update due to internal error. This bit is for test debug.
